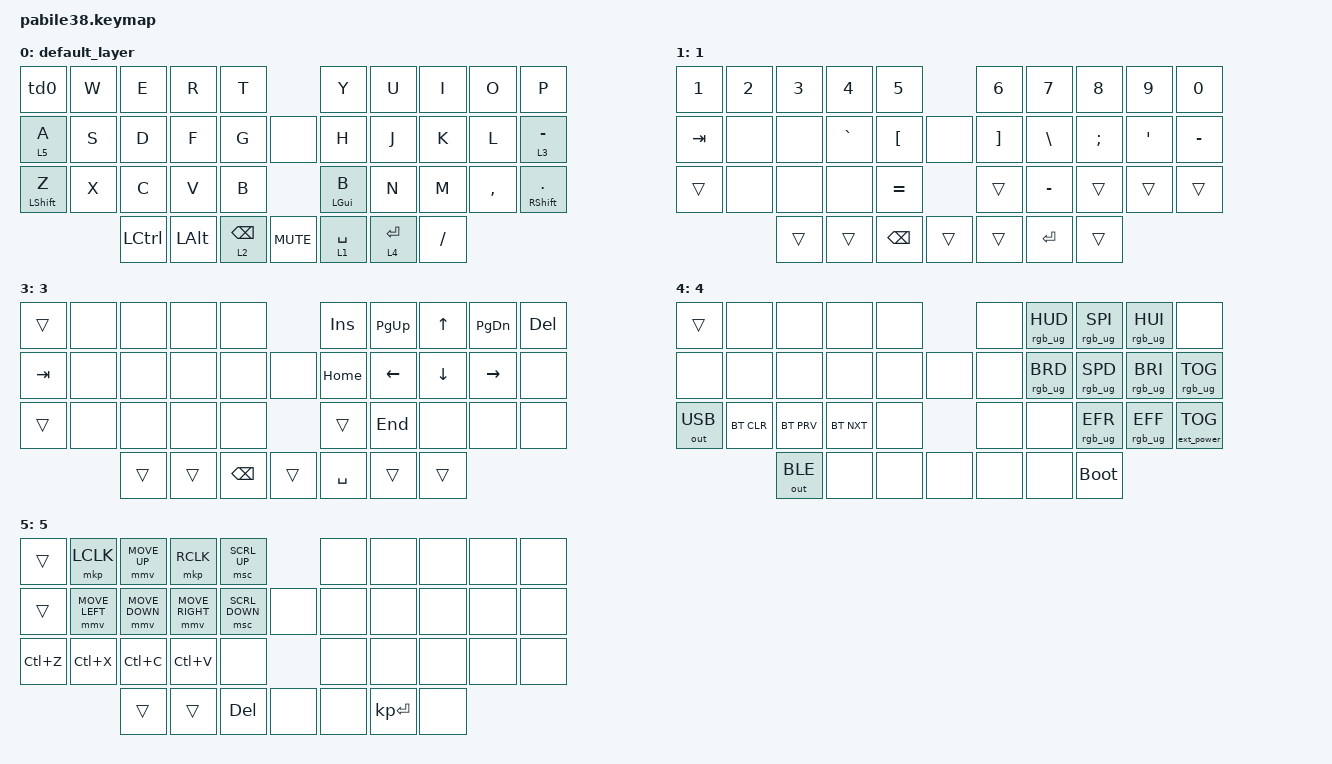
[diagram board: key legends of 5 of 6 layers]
/*
 * Copyright (c) 2023 The ZMK Contributors
 *
 * SPDX-License-Identifier: MIT
 */

#include <behaviors.dtsi>
#include <dt-bindings/zmk/keys.h>
#include <dt-bindings/zmk/bt.h>
#include <dt-bindings/zmk/outputs.h>
#include <dt-bindings/zmk/rgb.h>
#include <dt-bindings/zmk/ext_power.h>
#include <dt-bindings/zmk/pointing.h>

&mt {
    tapping-term-ms = <100>;
};
 
/ {
   behaviors {
        td0: tap_dance_0 {
            compatible = "zmk,behavior-tap-dance";
            label = "TAP_DANCE_0";
            #binding-cells = <0>;
            tapping-term-ms = <200>;
            bindings = <&kp Q>, <&kp ESC>, <&kp TILDE>;
        };
    };

	keymap {
		compatible = "zmk,keymap";

		default_layer {
			// --------------------------------------------------------------------------
			// |  Q   |  W   |  E   |  R   |  T   |         |   Y   |  U    |  I   |  O   |   P   | 
			// |  A   |  S   |  D   |  F   |  G   |   ENC0  |   H   |  J    |  K   |  L   |   -   | 
			// |  Z   |  X   |  C   |  V   |  B   |         | GUI   |  N    |  M   |  ,   |   .   |
			//               | LCTL | LALT | BSPC |   ENC1  | SPACE |  ENT  |  /   |

            sensor-bindings = <&inc_dec_kp C_VOL_UP C_VOL_DN &inc_dec_kp C_VOL_UP C_VOL_DN>;

			bindings = <
				&td0          &kp W    &kp E     &kp R    &kp T                  &kp Y       &kp U       &kp I     &kp O      &kp P
				&lt 5 A       &kp S    &kp D     &kp F    &kp G      &none       &kp H       &kp J       &kp K     &kp L      &lt 3 MINUS
				&mt LSHIFT Z  &kp X    &kp C     &kp V    &kp B                  &mt LGUI B  &kp N       &kp M     &kp COMMA  &mt RSHIFT DOT  
				                       &kp LCTRL &kp LALT &lt 2 BSPC &kp C_MUTE  &lt 1 SPACE &lt 4 ENTER &kp FSLH
			>;
		};
		1 {
			bindings = <
				&kp N1   &kp N2    &kp N3   &kp N4     &kp N5                &kp N6     &kp N7       &kp N8    &kp N9   &kp N0
				&kp TAB  &none     &none    &kp GRAVE  &kp LBKT   &none      &kp RBKT   &kp BSLH     &kp SEMI  &kp SQT  &kp MINUS
				&trans   &none     &none    &none      &kp EQUAL             &trans     &kp MINUS    &trans    &trans   &trans
				                   &trans   &trans     &kp BSPC   &trans     &trans     &kp ENTER    &trans    
			>;
		};
		2 {
			bindings = <
				&kp F1   &kp F2    &kp F3   &kp F4     &kp F5                &kp F6      &kp F7       &kp F8   &kp F9       &kp F10
				&kp TAB  &kp F11   &kp F12  &none      &none      &none      &none       &none        &none    &none        &kp MINUS
				&trans   &kp PSCRN &none    &none      &kp CAPS              &trans      &kp KP_NLCK  &none    &kp C_VOL_DN &kp C_VOL_UP 
				                   &trans   &trans     &trans     &trans     &kp SPACE   &kp KP_ENTER &trans   &kp C_MUTE
			>;
		};
		3 {
			bindings = <
				&trans   &none     &none    &none      &none                 &kp INS     &kp PAGE_UP  &kp UP      &kp PAGE_DOWN      &kp DEL
				&kp TAB  &none     &none    &none      &none      &none      &kp HOME    &kp LEFT     &kp DOWN    &kp RIGHT          &none
				&trans   &none     &none    &none      &none                 &trans      &kp END      &none       &none              &none
				                   &trans   &trans     &kp BSPC   &trans     &kp SPACE   &trans       &trans
			>;
		};
		4 {
			bindings = <
				&trans        &none       &none         &none      &none         &none    &rgb_ug RGB_HUD  &rgb_ug RGB_SPI  &rgb_ug RGB_HUI  &none
				&none         &none       &none         &none      &none  &none  &none    &rgb_ug RGB_BRD  &rgb_ug RGB_SPD  &rgb_ug RGB_BRI  &rgb_ug RGB_TOG
				&out OUT_USB  &bt BT_CLR  &bt BT_PRV    &bt BT_NXT &none         &none    &none            &rgb_ug RGB_EFR  &rgb_ug RGB_EFF  &ext_power EP_TOG
				                          &out OUT_BLE  &none      &none  &none  &none    &none &bootloader
			>;
		};
		5 {
			bindings = <
				&trans        &mkp LCLK      &mmv MOVE_UP   &mkp RCLK       &msc SCRL_UP     &none      &none  &none  &none  &none
				&trans        &mmv MOVE_LEFT &mmv MOVE_DOWN &mmv MOVE_RIGHT &msc SCRL_DOWN   &none  &none      &none  &none  &none  &none
				&kp LC(Z)     &kp LC(X)   &kp LC(C)     &kp LC(V)   &none          &none      &none  &none  &none  &none
				                          &trans        &trans      &kp DEL &none &none       &kp KP_ENTER  &none
			>;
		};
	};
};
